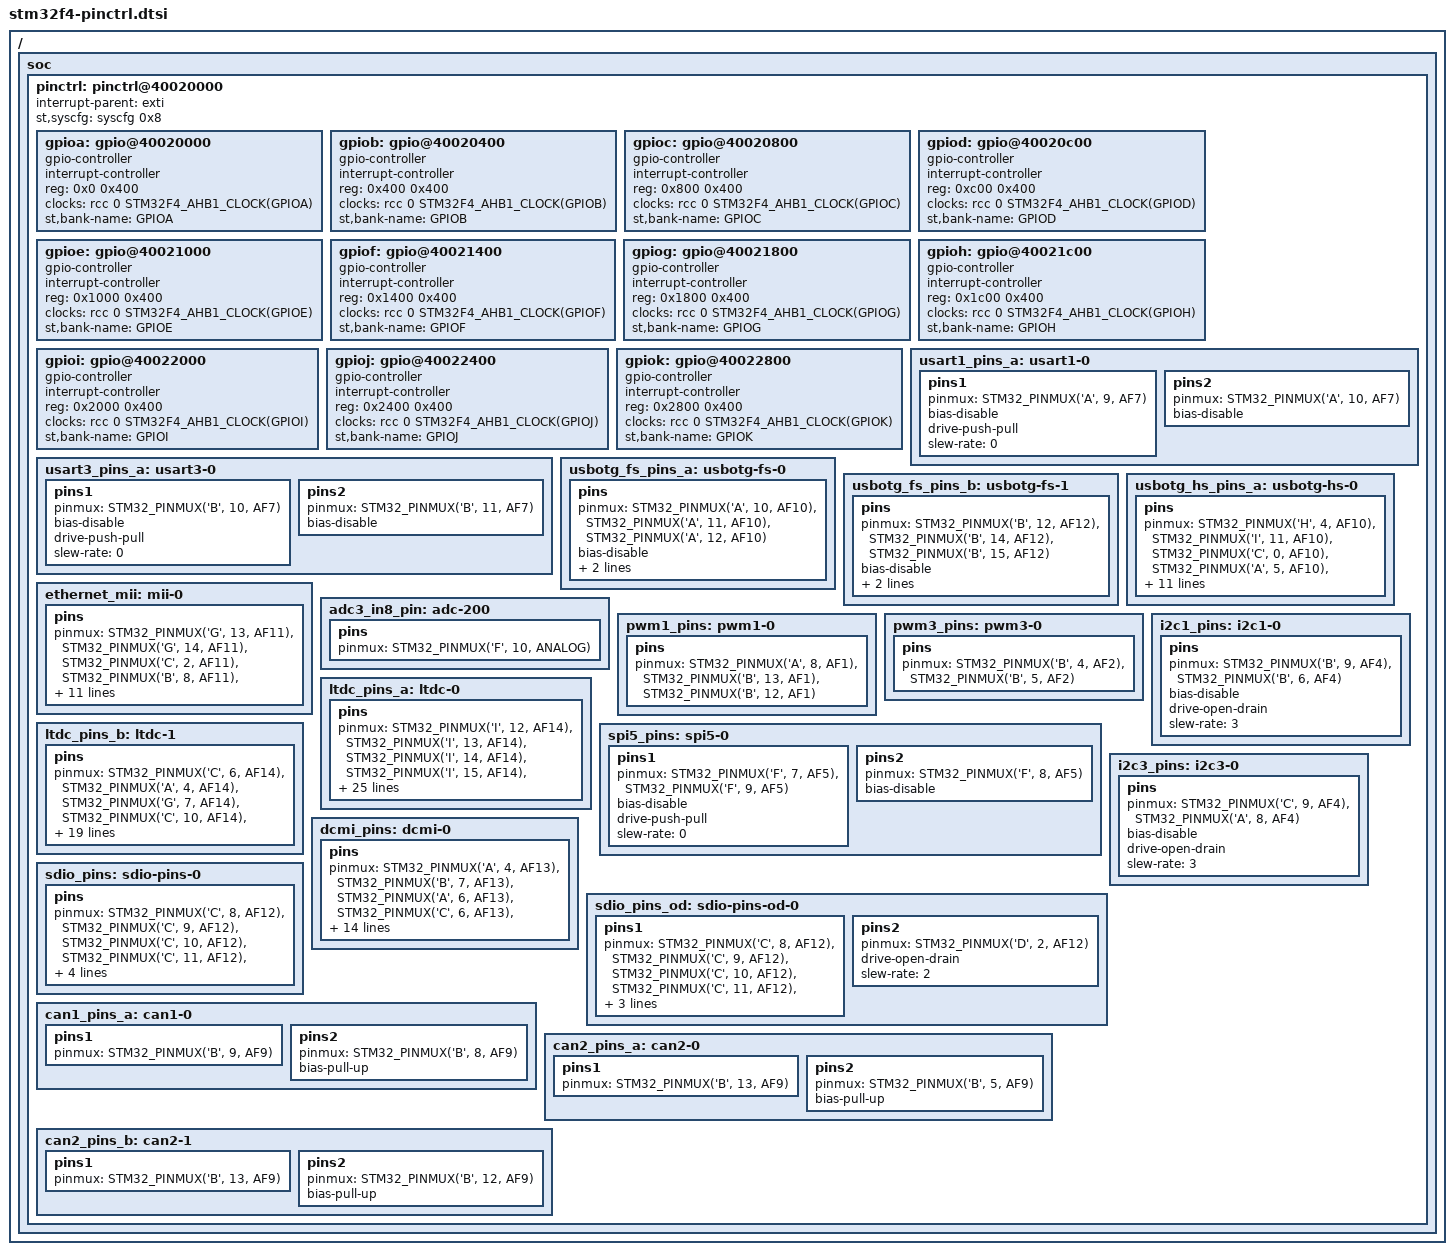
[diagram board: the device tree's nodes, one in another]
#include <dt-bindings/pinctrl/stm32-pinfunc.h>
#include <dt-bindings/mfd/stm32f4-rcc.h>
/ {
	soc {
		pinctrl: pinctrl@40020000 {
			#address-cells = <1>;
			#size-cells = <1>;
			ranges = <0 0x40020000 0x3000>;
			interrupt-parent = <&exti>;
			st,syscfg = <&syscfg 0x8>;
			gpioa: gpio@40020000 {
				gpio-controller;
				#gpio-cells = <2>;
				interrupt-controller;
				#interrupt-cells = <2>;
				reg = <0x0 0x400>;
				clocks = <&rcc 0 STM32F4_AHB1_CLOCK(GPIOA)>;
				st,bank-name = "GPIOA";
			};
			gpiob: gpio@40020400 {
				gpio-controller;
				#gpio-cells = <2>;
				interrupt-controller;
				#interrupt-cells = <2>;
				reg = <0x400 0x400>;
				clocks = <&rcc 0 STM32F4_AHB1_CLOCK(GPIOB)>;
				st,bank-name = "GPIOB";
			};
			gpioc: gpio@40020800 {
				gpio-controller;
				#gpio-cells = <2>;
				interrupt-controller;
				#interrupt-cells = <2>;
				reg = <0x800 0x400>;
				clocks = <&rcc 0 STM32F4_AHB1_CLOCK(GPIOC)>;
				st,bank-name = "GPIOC";
			};
			gpiod: gpio@40020c00 {
				gpio-controller;
				#gpio-cells = <2>;
				interrupt-controller;
				#interrupt-cells = <2>;
				reg = <0xc00 0x400>;
				clocks = <&rcc 0 STM32F4_AHB1_CLOCK(GPIOD)>;
				st,bank-name = "GPIOD";
			};
			gpioe: gpio@40021000 {
				gpio-controller;
				#gpio-cells = <2>;
				interrupt-controller;
				#interrupt-cells = <2>;
				reg = <0x1000 0x400>;
				clocks = <&rcc 0 STM32F4_AHB1_CLOCK(GPIOE)>;
				st,bank-name = "GPIOE";
			};
			gpiof: gpio@40021400 {
				gpio-controller;
				#gpio-cells = <2>;
				interrupt-controller;
				#interrupt-cells = <2>;
				reg = <0x1400 0x400>;
				clocks = <&rcc 0 STM32F4_AHB1_CLOCK(GPIOF)>;
				st,bank-name = "GPIOF";
			};
			gpiog: gpio@40021800 {
				gpio-controller;
				#gpio-cells = <2>;
				interrupt-controller;
				#interrupt-cells = <2>;
				reg = <0x1800 0x400>;
				clocks = <&rcc 0 STM32F4_AHB1_CLOCK(GPIOG)>;
				st,bank-name = "GPIOG";
			};
			gpioh: gpio@40021c00 {
				gpio-controller;
				#gpio-cells = <2>;
				interrupt-controller;
				#interrupt-cells = <2>;
				reg = <0x1c00 0x400>;
				clocks = <&rcc 0 STM32F4_AHB1_CLOCK(GPIOH)>;
				st,bank-name = "GPIOH";
			};
			gpioi: gpio@40022000 {
				gpio-controller;
				#gpio-cells = <2>;
				interrupt-controller;
				#interrupt-cells = <2>;
				reg = <0x2000 0x400>;
				clocks = <&rcc 0 STM32F4_AHB1_CLOCK(GPIOI)>;
				st,bank-name = "GPIOI";
			};
			gpioj: gpio@40022400 {
				gpio-controller;
				#gpio-cells = <2>;
				interrupt-controller;
				#interrupt-cells = <2>;
				reg = <0x2400 0x400>;
				clocks = <&rcc 0 STM32F4_AHB1_CLOCK(GPIOJ)>;
				st,bank-name = "GPIOJ";
			};
			gpiok: gpio@40022800 {
				gpio-controller;
				#gpio-cells = <2>;
				interrupt-controller;
				#interrupt-cells = <2>;
				reg = <0x2800 0x400>;
				clocks = <&rcc 0 STM32F4_AHB1_CLOCK(GPIOK)>;
				st,bank-name = "GPIOK";
			};
			usart1_pins_a: usart1-0 {
				pins1 {
					pinmux = <STM32_PINMUX('A', 9, AF7)>;  
					bias-disable;
					drive-push-pull;
					slew-rate = <0>;
				};
				pins2 {
					pinmux = <STM32_PINMUX('A', 10, AF7)>;  
					bias-disable;
				};
			};
			usart3_pins_a: usart3-0 {
				pins1 {
					pinmux = <STM32_PINMUX('B', 10, AF7)>;  
					bias-disable;
					drive-push-pull;
					slew-rate = <0>;
				};
				pins2 {
					pinmux = <STM32_PINMUX('B', 11, AF7)>;  
					bias-disable;
				};
			};
			usbotg_fs_pins_a: usbotg-fs-0 {
				pins {
					pinmux = <STM32_PINMUX('A', 10, AF10)>,  
						 <STM32_PINMUX('A', 11, AF10)>,  
						 <STM32_PINMUX('A', 12, AF10)>;  
					bias-disable;
					drive-push-pull;
					slew-rate = <2>;
				};
			};
			usbotg_fs_pins_b: usbotg-fs-1 {
				pins {
					pinmux = <STM32_PINMUX('B', 12, AF12)>,  
						 <STM32_PINMUX('B', 14, AF12)>,  
						 <STM32_PINMUX('B', 15, AF12)>;  
					bias-disable;
					drive-push-pull;
					slew-rate = <2>;
				};
			};
			usbotg_hs_pins_a: usbotg-hs-0 {
				pins {
					pinmux = <STM32_PINMUX('H', 4, AF10)>,  
						 <STM32_PINMUX('I', 11, AF10)>,  
						 <STM32_PINMUX('C', 0, AF10)>,  
						 <STM32_PINMUX('A', 5, AF10)>,  
						 <STM32_PINMUX('A', 3, AF10)>,  
						 <STM32_PINMUX('B', 0, AF10)>,  
						 <STM32_PINMUX('B', 1, AF10)>,  
						 <STM32_PINMUX('B', 10, AF10)>,  
						 <STM32_PINMUX('B', 11, AF10)>,  
						 <STM32_PINMUX('B', 12, AF10)>,  
						 <STM32_PINMUX('B', 13, AF10)>,  
						 <STM32_PINMUX('B', 5, AF10)>;  
					bias-disable;
					drive-push-pull;
					slew-rate = <2>;
				};
			};
			ethernet_mii: mii-0 {
				pins {
					pinmux = <STM32_PINMUX('G', 13, AF11)>,  
						 <STM32_PINMUX('G', 14, AF11)>,  
						 <STM32_PINMUX('C', 2, AF11)>,  
						 <STM32_PINMUX('B', 8, AF11)>,  
						 <STM32_PINMUX('C', 3, AF11)>,  
						 <STM32_PINMUX('G', 11,AF11)>,  
						 <STM32_PINMUX('A', 2, AF11)>,  
						 <STM32_PINMUX('C', 1, AF11)>,  
						 <STM32_PINMUX('A', 1, AF11)>,  
						 <STM32_PINMUX('A', 7, AF11)>,  
						 <STM32_PINMUX('C', 4, AF11)>,  
						 <STM32_PINMUX('C', 5, AF11)>,  
						 <STM32_PINMUX('H', 6, AF11)>,  
						 <STM32_PINMUX('H', 7, AF11)>;  
					slew-rate = <2>;
				};
			};
			adc3_in8_pin: adc-200 {
				pins {
					pinmux = <STM32_PINMUX('F', 10, ANALOG)>;
				};
			};
			pwm1_pins: pwm1-0 {
				pins {
					pinmux = <STM32_PINMUX('A', 8, AF1)>,  
						 <STM32_PINMUX('B', 13, AF1)>,  
						 <STM32_PINMUX('B', 12, AF1)>;  
				};
			};
			pwm3_pins: pwm3-0 {
				pins {
					pinmux = <STM32_PINMUX('B', 4, AF2)>,  
						 <STM32_PINMUX('B', 5, AF2)>;  
				};
			};
			i2c1_pins: i2c1-0 {
				pins {
					pinmux = <STM32_PINMUX('B', 9, AF4)>,  
						 <STM32_PINMUX('B', 6, AF4)>;  
					bias-disable;
					drive-open-drain;
					slew-rate = <3>;
				};
			};
			ltdc_pins_a: ltdc-0 {
				pins {
					pinmux = <STM32_PINMUX('I', 12, AF14)>,  
						 <STM32_PINMUX('I', 13, AF14)>,  
						 <STM32_PINMUX('I', 14, AF14)>,  
						 <STM32_PINMUX('I', 15, AF14)>,  
						 <STM32_PINMUX('J', 0, AF14)>,  
						 <STM32_PINMUX('J', 1, AF14)>,  
						 <STM32_PINMUX('J', 2, AF14)>,  
						 <STM32_PINMUX('J', 3, AF14)>,  
						 <STM32_PINMUX('J', 4, AF14)>,  
						 <STM32_PINMUX('J', 5, AF14)>,  
						 <STM32_PINMUX('J', 6, AF14)>,  
						 <STM32_PINMUX('J', 7, AF14)>,  
						 <STM32_PINMUX('J', 8, AF14)>,  
						 <STM32_PINMUX('J', 9, AF14)>,  
						 <STM32_PINMUX('J', 10, AF14)>,  
						 <STM32_PINMUX('J', 11, AF14)>,  
						 <STM32_PINMUX('J', 12, AF14)>,  
						 <STM32_PINMUX('J', 13, AF14)>,  
						 <STM32_PINMUX('J', 14, AF14)>,  
						 <STM32_PINMUX('J', 15, AF14)>,  
						 <STM32_PINMUX('K', 0, AF14)>,  
						 <STM32_PINMUX('K', 1, AF14)>,  
						 <STM32_PINMUX('K', 2, AF14)>,  
						 <STM32_PINMUX('K', 3, AF14)>,  
						 <STM32_PINMUX('K', 4, AF14)>,  
						 <STM32_PINMUX('K', 5, AF14)>,  
						 <STM32_PINMUX('K', 6, AF14)>,  
						 <STM32_PINMUX('K', 7, AF14)>;  
					slew-rate = <2>;
				};
			};
			ltdc_pins_b: ltdc-1 {
				pins {
					pinmux = <STM32_PINMUX('C', 6,  AF14)>,
						 <STM32_PINMUX('A', 4,  AF14)>,
						 <STM32_PINMUX('G', 7,  AF14)>,
						 <STM32_PINMUX('C', 10, AF14)>,
						 <STM32_PINMUX('B', 0,  AF9)>,
						 <STM32_PINMUX('A', 11, AF14)>,
						 <STM32_PINMUX('A', 12, AF14)>,
						 <STM32_PINMUX('B', 1,  AF9)>,
						 <STM32_PINMUX('G', 6,  AF14)>,
						 <STM32_PINMUX('A', 6,  AF14)>,
						 <STM32_PINMUX('G', 10, AF9)>,
						 <STM32_PINMUX('B', 10, AF14)>,
						 <STM32_PINMUX('D', 6,  AF14)>,
						 <STM32_PINMUX('G', 11, AF14)>,
						 <STM32_PINMUX('B', 11, AF14)>,
						 <STM32_PINMUX('C', 7,  AF14)>,
						 <STM32_PINMUX('D', 3,  AF14)>,
						 <STM32_PINMUX('G', 12, AF9)>,
						 <STM32_PINMUX('A', 3,  AF14)>,
						 <STM32_PINMUX('B', 8,  AF14)>,
						 <STM32_PINMUX('B', 9,  AF14)>,
						 <STM32_PINMUX('F', 10, AF14)>;
					slew-rate = <2>;
				};
			};
			spi5_pins: spi5-0 {
				pins1 {
					pinmux = <STM32_PINMUX('F', 7, AF5)>,
						 <STM32_PINMUX('F', 9, AF5)>;
					bias-disable;
					drive-push-pull;
					slew-rate = <0>;
				};
				pins2 {
					pinmux = <STM32_PINMUX('F', 8, AF5)>;
					bias-disable;
				};
			};
			i2c3_pins: i2c3-0 {
				pins {
					pinmux = <STM32_PINMUX('C', 9, AF4)>,
						 <STM32_PINMUX('A', 8, AF4)>;
					bias-disable;
					drive-open-drain;
					slew-rate = <3>;
				};
			};
			dcmi_pins: dcmi-0 {
				pins {
					pinmux = <STM32_PINMUX('A', 4, AF13)>,  
						 <STM32_PINMUX('B', 7, AF13)>,  
						 <STM32_PINMUX('A', 6, AF13)>,  
						 <STM32_PINMUX('C', 6, AF13)>,  
						 <STM32_PINMUX('C', 7, AF13)>,  
						 <STM32_PINMUX('C', 8, AF13)>,  
						 <STM32_PINMUX('C', 9, AF13)>,  
						 <STM32_PINMUX('C', 11, AF13)>,  
						 <STM32_PINMUX('D', 3, AF13)>,  
						 <STM32_PINMUX('B', 8, AF13)>,  
						 <STM32_PINMUX('E', 6, AF13)>,  
						 <STM32_PINMUX('C', 10, AF13)>,  
						 <STM32_PINMUX('C', 12, AF13)>,  
						 <STM32_PINMUX('D', 6, AF13)>,  
						 <STM32_PINMUX('D', 2, AF13)>;  
					bias-disable;
					drive-push-pull;
					slew-rate = <3>;
				};
			};
			sdio_pins: sdio-pins-0 {
				pins {
					pinmux = <STM32_PINMUX('C', 8, AF12)>,  
						 <STM32_PINMUX('C', 9, AF12)>,  
						 <STM32_PINMUX('C', 10, AF12)>,  
						 <STM32_PINMUX('C', 11, AF12)>,  
						 <STM32_PINMUX('C', 12, AF12)>,  
						 <STM32_PINMUX('D', 2, AF12)>;  
					drive-push-pull;
					slew-rate = <2>;
				};
			};
			sdio_pins_od: sdio-pins-od-0 {
				pins1 {
					pinmux = <STM32_PINMUX('C', 8, AF12)>,  
						 <STM32_PINMUX('C', 9, AF12)>,  
						 <STM32_PINMUX('C', 10, AF12)>,  
						 <STM32_PINMUX('C', 11, AF12)>,  
						 <STM32_PINMUX('C', 12, AF12)>;  
					drive-push-pull;
					slew-rate = <2>;
				};
				pins2 {
					pinmux = <STM32_PINMUX('D', 2, AF12)>;  
					drive-open-drain;
					slew-rate = <2>;
				};
			};
			can1_pins_a: can1-0 {
				pins1 {
					pinmux = <STM32_PINMUX('B', 9, AF9)>;  
				};
				pins2 {
					pinmux = <STM32_PINMUX('B', 8, AF9)>;  
					bias-pull-up;
				};
			};
			can2_pins_a: can2-0 {
				pins1 {
					pinmux = <STM32_PINMUX('B', 13, AF9)>;  
				};
				pins2 {
					pinmux = <STM32_PINMUX('B', 5, AF9)>;  
					bias-pull-up;
				};
			};
			can2_pins_b: can2-1 {
				pins1 {
					pinmux = <STM32_PINMUX('B', 13, AF9)>;  
				};
				pins2 {
					pinmux = <STM32_PINMUX('B', 12, AF9)>;  
					bias-pull-up;
				};
			};
		};
	};
};
